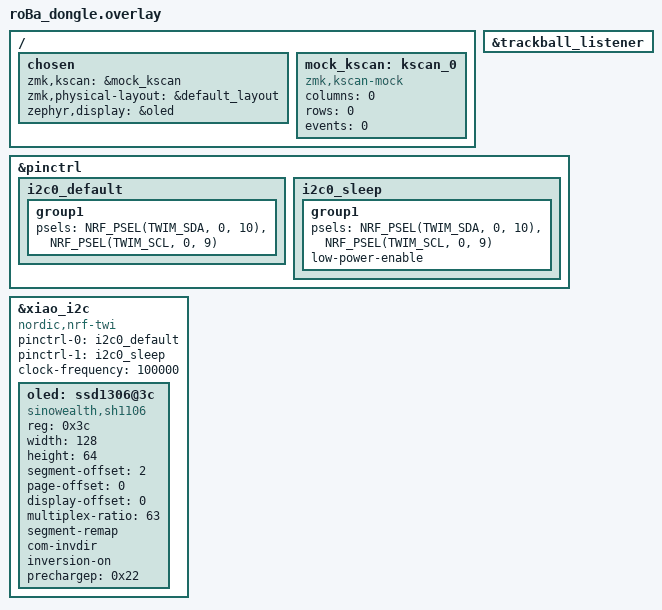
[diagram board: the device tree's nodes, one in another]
#include "roBa.dtsi"
#include "roBa_trackball.dtsi"

/ {
    chosen {
        zmk,kscan = &mock_kscan;
        zmk,physical-layout = &default_layout;
        zephyr,display = &oled;
    };

    mock_kscan: kscan_0 {
        compatible = "zmk,kscan-mock";
        columns = <0>;
        rows = <0>;
        events = <0>;
    };
};

&trackball_listener {
    status = "okay";  
    };

&pinctrl {
    i2c0_default: i2c0_default {
        group1 {
            psels = <NRF_PSEL(TWIM_SDA, 0, 10)>,
                    <NRF_PSEL(TWIM_SCL, 0, 9)>;
        };
    };
      
    i2c0_sleep: i2c0_sleep {
        group1 {
            psels = <NRF_PSEL(TWIM_SDA, 0, 10)>,
                    <NRF_PSEL(TWIM_SCL, 0, 9)>;
            low-power-enable;
        };
    };
};


&xiao_i2c {
    status = "okay";
    compatible = "nordic,nrf-twi";
    pinctrl-0 = <&i2c0_default>;
    pinctrl-1 = <&i2c0_sleep>;
    pinctrl-names = "default", "sleep";
    
    clock-frequency = <100000>;

    oled: ssd1306@3c {
        compatible = "sinowealth,sh1106";
        reg = <0x3c>;
        width = <128>;
        height = <64>;
        segment-offset = <2>;
        page-offset = <0>;
        display-offset = <0>;
        multiplex-ratio = <63>;
        segment-remap;
        com-invdir;
        inversion-on;
        prechargep = <0x22>;
    };
};
